# PIC24FJ256GB110 register map
Vendor: Microchip
Architecture 24xxxx. Special function registers and configuration words.
Registers are 16-bit, read-write, reset 0x0 unless marked. A register's access mark holds for its fields unless they carry their own. Addresses are absolute, and some are shared; only a register's first bit layout is shown; lines under a group give offsets from that group; [hi:lo] are bit positions; {n}, {i} and the like mark numbered series; 'fields as' and 'values as' point back to an identical list; <NAME> marks a mode.

## Further device data
pins=1: MCLR; 2: PGEC3/AN5/C1INA/Vbuson/RP18/CN7/RB5; 3: PGED3/AN4/C1INB/USBOEN/RP28/CN6/RB4; 4: PGEC1/AN1/RP1/CN3/RB1; 5: PGED1/AN0/RP0/CN2/RB0; 6: PGEC2/AN6/RP6/CN24/RB6; 7: PGED2/AN7/RP7/RCV/CN25/RB7

## SFR
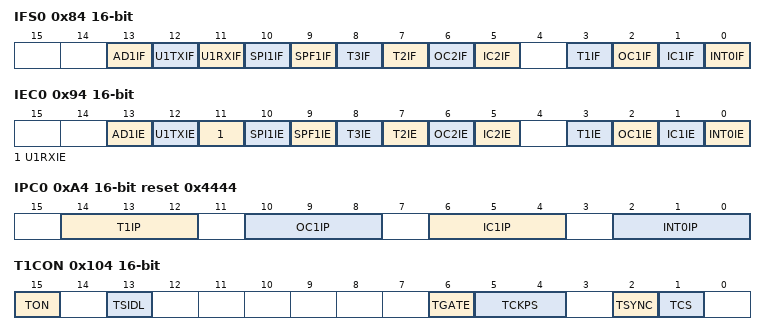
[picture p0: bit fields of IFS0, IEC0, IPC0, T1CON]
0x84 IFS0
  [13] AD1IF, [12] U1TXIF, [11] U1RXIF, [10] SPI1IF, [9] SPF1IF, [8] T3IF, [7] T2IF, [6] OC2IF, [5] IC2IF, [3] T1IF, [2] OC1IF, [1] IC1IF, [0] INT0IF
0x94 IEC0
  [13] AD1IE, [12] U1TXIE, [11] U1RXIE, [10] SPI1IE, [9] SPF1IE, [8] T3IE, [7] T2IE, [6] OC2IE, [5] IC2IE, [3] T1IE, [2] OC1IE, [1] IC1IE, [0] INT0IE
0xA4 IPC0 reset 0x4444
  [14:12] T1IP, [10:8] OC1IP, [6:4] IC1IP, [2:0] INT0IP
0x100 TMR1 reset not defined — (power-on value xxxxxxxxxxxxxxxx)
0x102 PR1 reset 0xFFFF
0x104 T1CON
  [15] TON, [13] TSIDL, [6] TGATE, [5:4] TCKPS, [2] TSYNC, [1] TCS
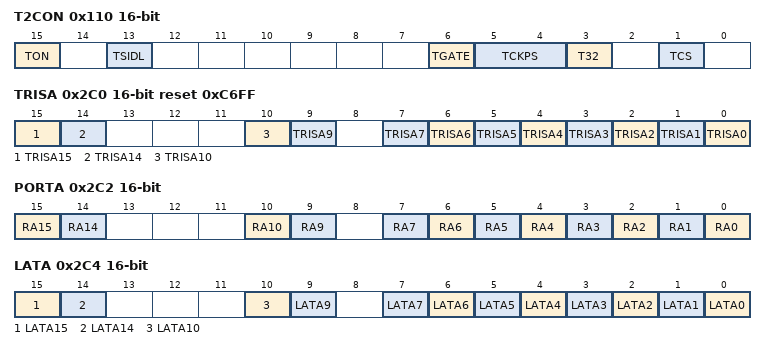
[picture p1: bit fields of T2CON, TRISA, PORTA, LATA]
0x110 T2CON
  [15] TON, [13] TSIDL, [6] TGATE, [5:4] TCKPS, [3] T32, [1] TCS
0x2C0 TRISA reset 0xC6FF
  [15] TRISA15, [14] TRISA14, [10] TRISA10, [9] TRISA9, [n] TRISA{n} (n=0..7)
0x2C2 PORTA reset not defined — (power-on value xx---xx-xxxxxxxx)
  [15] RA15, [14] RA14, [10] RA10, [9] RA9, [n] RA{n} (n=0..7)
0x2C4 LATA reset not defined — (power-on value xx---xx-xxxxxxxx)
  [15] LATA15, [14] LATA14, [10] LATA10, [9] LATA9, [n] LATA{n} (n=0..7)
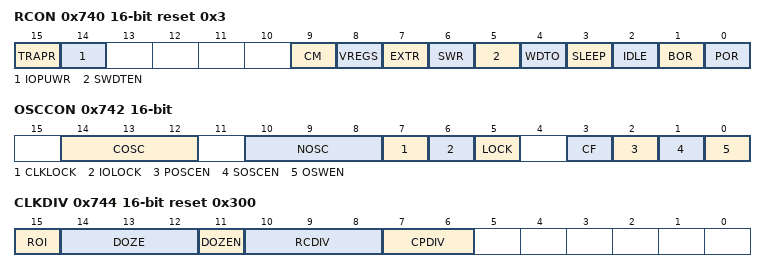
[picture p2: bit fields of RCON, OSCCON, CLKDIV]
0x740 RCON reset 0x3
  [15] TRAPR, [14] IOPUWR, [9] CM, [8] VREGS, [7] EXTR, [6] SWR, [5] SWDTEN, [4] WDTO, [3] SLEEP, [2] IDLE, [1] BOR, [0] POR
0x742 OSCCON reset not defined — (power-on value -000-yyy00000000)
  [14:12] COSC ro, [10:8] NOSC, [7] CLKLOCK ro, [6] IOLOCK, [5] LOCK ro, [3] CF ro, [2] POSCEN, [1] SOSCEN, [0] OSWEN
0x744 CLKDIV reset 0x300
  [15] ROI, [14:12] DOZE, [11] DOZEN, [10:8] RCDIV, [7:6] CPDIV
